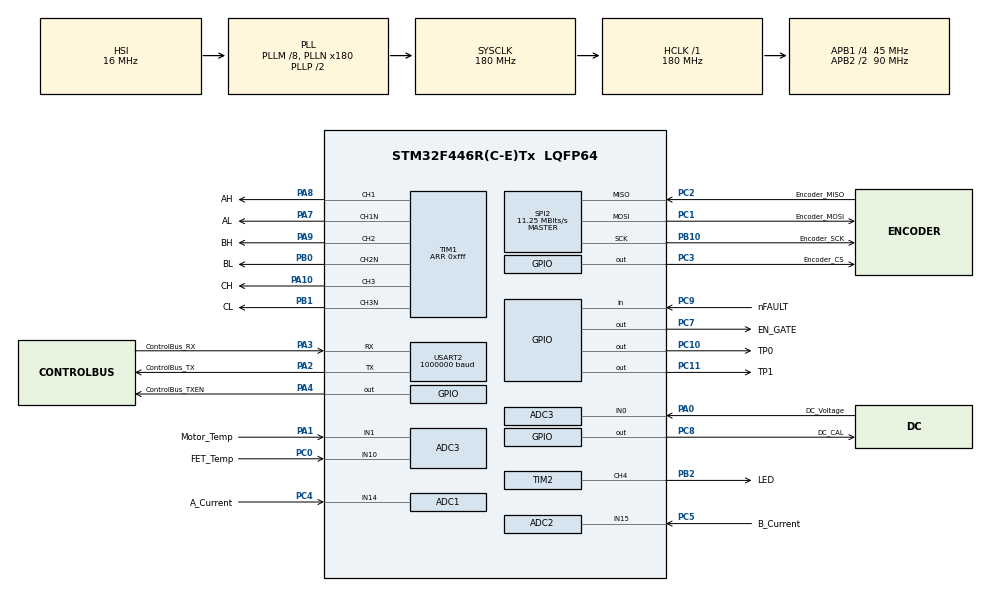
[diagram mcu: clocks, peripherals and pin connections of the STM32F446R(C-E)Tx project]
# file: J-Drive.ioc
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ADC1.Channel-0\#ChannelRegularConversion=ADC_CHANNEL_14
ADC1.ClockPrescaler=ADC_CLOCK_SYNC_PCLK_DIV4
ADC1.ExternalTrigConv=ADC_EXTERNALTRIGCONV_T8_TRGO
ADC1.NbrOfConversion=1
ADC1.NbrOfConversionFlag=1
ADC1.Rank-0\#ChannelRegularConversion=1
ADC1.SamplingTime-0\#ChannelRegularConversion=ADC_SAMPLETIME_3CYCLES
ADC1.master=1
ADC2.Channel-0\#ChannelRegularConversion=ADC_CHANNEL_15
ADC2.ClockPrescaler=ADC_CLOCK_SYNC_PCLK_DIV4
ADC2.ExternalTrigConv=ADC_EXTERNALTRIGCONV_T8_TRGO
ADC2.NbrOfConversion=1
ADC2.NbrOfConversionFlag=1
ADC2.Rank-0\#ChannelRegularConversion=1
ADC2.SamplingTime-0\#ChannelRegularConversion=ADC_SAMPLETIME_3CYCLES
ADC3.Channel-0\#ChannelRegularConversion=ADC_CHANNEL_0
ADC3.Channel-1\#ChannelRegularConversion=ADC_CHANNEL_1
ADC3.Channel-2\#ChannelRegularConversion=ADC_CHANNEL_10
ADC3.ClockPrescaler=ADC_CLOCK_SYNC_PCLK_DIV4
ADC3.DiscontinuousConvMode=ENABLE
ADC3.ExternalTrigConv=ADC_EXTERNALTRIGCONV_T8_TRGO
ADC3.InjNumberOfConversion=0
ADC3.NbrOfConversion=3
ADC3.NbrOfConversionFlag=1
ADC3.NbrOfDiscConversion=1
ADC3.Rank-0\#ChannelRegularConversion=1
ADC3.Rank-1\#ChannelRegularConversion=2
ADC3.Rank-2\#ChannelRegularConversion=3
ADC3.SamplingTime-0\#ChannelRegularConversion=ADC_SAMPLETIME_3CYCLES
ADC3.SamplingTime-1\#ChannelRegularConversion=ADC_SAMPLETIME_3CYCLES
ADC3.SamplingTime-2\#ChannelRegularConversion=ADC_SAMPLETIME_3CYCLES
ADC3.ScanConvMode=ENABLE
Dma.Request0=USART2_RX
Dma.USART2_RX.0.Direction=DMA_PERIPH_TO_MEMORY
Dma.USART2_RX.0.FIFOMode=DMA_FIFOMODE_DISABLE
Dma.USART2_RX.0.Instance=DMA1_Stream5
Dma.USART2_RX.0.MemDataAlignment=DMA_MDATAALIGN_BYTE
Dma.USART2_RX.0.MemInc=DMA_MINC_ENABLE
Dma.USART2_RX.0.Mode=DMA_CIRCULAR
Dma.USART2_RX.0.PeriphDataAlignment=DMA_PDATAALIGN_BYTE
Dma.USART2_RX.0.PeriphInc=DMA_PINC_DISABLE
Dma.USART2_RX.0.Priority=DMA_PRIORITY_LOW
Mcu.Family=STM32F4
Mcu.Name=STM32F446R(C-E)Tx
Mcu.Package=LQFP64
Mcu.UserConstants=DEADTIME_CLK,0
NVIC.DMA1_Stream5_IRQn=true\:0\:0\:false\:false\:true\:false\:true
NVIC.PriorityGroup=NVIC_PRIORITYGROUP_2
NVIC.SPI2_IRQn=true\:3\:3\:true\:false\:true\:true\:true
NVIC.TIM1_UP_TIM10_IRQn=true\:1\:1\:true\:false\:true\:true\:true
NVIC.TIM8_UP_TIM13_IRQn=true\:1\:1\:true\:false\:true\:true\:true
NVIC.USART2_IRQn=true\:1\:1\:true\:false\:true\:true\:true
PA0-WKUP.GPIO_Label=DC_Voltage
PA0-WKUP.Signal=ADCx_IN0
PA1.GPIO_Label=Motor_Temp
PA1.Signal=ADCx_IN1
PA10.GPIO_Label=CH
PA10.Signal=S_TIM1_CH3
PA13.GPIO_Label=TMS
PA13.Mode=Serial_Wire
PA13.Signal=SYS_JTMS-SWDIO
PA14.GPIO_Label=TCK
PA14.Mode=Serial_Wire
PA14.Signal=SYS_JTCK-SWCLK
PA2.GPIO_Label=ControlBus_TX
PA2.GPIO_PuPd=GPIO_PULLUP
PA2.Mode=Asynchronous
PA2.Signal=USART2_TX
PA3.GPIO_Label=ControlBus_RX
PA3.GPIO_PuPd=GPIO_PULLUP
PA3.Mode=Asynchronous
PA3.Signal=USART2_RX
PA4.GPIO_Label=ControlBus_TXEN
PA4.GPIO_Speed=GPIO_SPEED_FREQ_VERY_HIGH
PA4.Signal=GPIO_Output
PA7.GPIO_Label=AL
PA7.Mode=PWM Generation1 CH1 CH1N
PA7.Signal=TIM1_CH1N
PA8.GPIO_Label=AH
PA8.Signal=S_TIM1_CH1
PA9.GPIO_Label=BH
PA9.Signal=S_TIM1_CH2
PB0.GPIO_Label=BL
PB0.Mode=PWM Generation2 CH2 CH2N
PB0.Signal=TIM1_CH2N
PB1.GPIO_Label=CL
PB1.Mode=PWM Generation3 CH3 CH3N
PB1.Signal=TIM1_CH3N
PB10.GPIO_Label=Encoder_SCK
PB10.Mode=Full_Duplex_Master
PB10.Signal=SPI2_SCK
PB2.GPIO_Label=LED
PB2.Signal=S_TIM2_CH4
PB3.GPIO_Label=SWO
PB3.Signal=SYS_JTDO-SWO
PC0.GPIO_Label=FET_Temp
PC0.Signal=ADCx_IN10
PC1.GPIO_Label=Encoder_MOSI
PC1.Mode=Full_Duplex_Master
PC1.Signal=SPI2_MOSI
PC10.GPIO_Label=TP0
PC10.GPIO_ModeDefaultOutputPP=GPIO_MODE_OUTPUT_PP
PC10.GPIO_Speed=GPIO_SPEED_FREQ_VERY_HIGH
PC10.Signal=GPIO_Output
PC11.GPIO_Label=TP1
PC11.GPIO_Speed=GPIO_SPEED_FREQ_VERY_HIGH
PC11.Signal=GPIO_Output
PC2.GPIO_Label=Encoder_MISO
PC2.GPIO_PuPd=GPIO_NOPULL
PC2.Mode=Full_Duplex_Master
PC2.Signal=SPI2_MISO
PC3.GPIO_Label=Encoder_CS
PC3.Signal=GPIO_Output
PC4.GPIO_Label=A_Current
PC4.Signal=ADCx_IN14
PC5.GPIO_Label=B_Current
PC5.Signal=ADCx_IN15
PC7.GPIO_Label=EN_GATE
PC7.Signal=GPIO_Output
PC8.GPIO_Label=DC_CAL
PC8.Signal=GPIO_Output
PC9.GPIO_Label=nFAULT
PC9.GPIO_PuPd=GPIO_PULLUP
PC9.Signal=GPIO_Input
ProjectManager.HeapSize=0xFF00
ProjectManager.StackSize=0xFF00
ProjectManager.TargetToolchain=STM32CubeIDE
RCC.48MHZClocksFreq_Value=84000000
RCC.AHBFreq_Value=180000000
RCC.APB1CLKDivider=RCC_HCLK_DIV4
RCC.APB1Freq_Value=45000000
RCC.APB1TimFreq_Value=90000000
RCC.APB2CLKDivider=RCC_HCLK_DIV2
RCC.APB2Freq_Value=90000000
RCC.APB2TimFreq_Value=180000000
RCC.CortexFreq_Value=180000000
RCC.FLatency-AdvancedSettings=FLASH_LATENCY_5
RCC.HCLKFreq_Value=180000000
RCC.HSE_VALUE=8000000
RCC.HSI_VALUE=16000000
RCC.PLLM=8
RCC.PLLN=180
RCC.SYSCLKFreq_VALUE=180000000
RCC.SYSCLKSource=RCC_SYSCLKSOURCE_PLLCLK
RCC.USBFreq_Value=180000000
RCC.VCOOutputFreq_Value=360000000
SH.ADCx_IN0.0=ADC3_IN0,IN0
SH.ADCx_IN1.0=ADC3_IN1,IN1
SH.ADCx_IN10.0=ADC3_IN10,IN10
SH.ADCx_IN14.0=ADC1_IN14,IN14
SH.ADCx_IN15.0=ADC2_IN15,IN15
SH.S_TIM1_CH1.0=TIM1_CH1,PWM Generation1 CH1 CH1N
SH.S_TIM1_CH2.0=TIM1_CH2,PWM Generation2 CH2 CH2N
SH.S_TIM1_CH3.0=TIM1_CH3,PWM Generation3 CH3 CH3N
SH.S_TIM2_CH4.0=TIM2_CH4,PWM Generation4 CH4
SPI2.BaudRatePrescaler=SPI_BAUDRATEPRESCALER_4
SPI2.CLKPhase=SPI_PHASE_2EDGE
SPI2.CalculateBaudRate=11.25 MBits/s
SPI2.Direction=SPI_DIRECTION_2LINES
SPI2.Mode=SPI_MODE_MASTER
SPI2.VirtualType=VM_MASTER
TIM1.Channel-PWM\ Generation1\ CH1\ CH1N=TIM_CHANNEL_1
TIM1.Channel-PWM\ Generation2\ CH2\ CH2N=TIM_CHANNEL_2
TIM1.Channel-PWM\ Generation3\ CH3\ CH3N=TIM_CHANNEL_3
TIM1.ClockDivision=TIM_CLOCKDIVISION_DIV1
TIM1.CounterMode=TIM_COUNTERMODE_CENTERALIGNED2
TIM1.DeadTime=DEADTIME_CLK
TIM1.Period=0xfff
TIM1.RepetitionCounter=1
TIM2.Channel-PWM\ Generation4\ CH4=TIM_CHANNEL_4
TIM2.Period=0xfff
TIM8.Period=0xfff
TIM8.TIM_MasterOutputTrigger=TIM_TRGO_UPDATE
TIM8.TIM_MasterSlaveMode=TIM_MASTERSLAVEMODE_ENABLE
USART2.BaudRate=1000000
USART2.OverSampling=UART_OVERSAMPLING_16
USART2.VirtualMode=VM_ASYNC
VP_CRC_VS_CRC.Mode=CRC_Activate
VP_TIM1_VS_ClockSourceINT.Mode=Internal
VP_TIM2_VS_ClockSourceINT.Mode=Internal
VP_TIM8_VS_ClockSourceINT.Mode=Internal
board=NUCLEO-F446RE

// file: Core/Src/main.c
/* USER CODE BEGIN Header */
/**
  ******************************************************************************
  * @file           : main.c
  * @brief          : Main program body
  ******************************************************************************
  * @attention
  *
  * <h2><center>&copy; Copyright (c) 2020 STMicroelectronics.
  * All rights reserved.</center></h2>
  *
  * This software component is licensed by ST under BSD 3-Clause license,
  * the "License"; You may not use this file except in compliance with the
  * License. You may obtain a copy of the License at:
  *                        opensource.org/licenses/BSD-3-Clause
  *
  ******************************************************************************
  */
/* USER CODE END Header */
#include "main.h"
#include "adc.h"
#include "crc.h"
#include "dma.h"
#include "spi.h"
#include "tim.h"
#include "usart.h"
#include "gpio.h"

/* USER CODE BEGIN Includes */
#include <jdrive_main.hpp>
/* USER CODE END Includes */

void SystemClock_Config(void);
/* USER CODE BEGIN PFP */
int _write(int fd, char *str, int len)
{
	HAL_GPIO_WritePin(ControlBus_TXEN_GPIO_Port, ControlBus_TXEN_Pin, GPIO_PIN_SET);
	HAL_UART_Transmit_IT(&huart2, (uint8_t *)str, len);
	return len;
}

/* USER CODE END PFP */

int main(void)
{

  /* MCU Configuration--------------------------------------------------------*/

  /* Reset of all peripherals, Initializes the Flash interface and the Systick. */
  HAL_Init();

  /* Configure the system clock */
  SystemClock_Config();

  /* Initialize all configured peripherals */
  MX_GPIO_Init();
  MX_DMA_Init();
  MX_TIM2_Init();
  MX_CRC_Init();
  MX_USART2_UART_Init();
  MX_ADC1_Init();
  MX_ADC2_Init();
  MX_ADC3_Init();
  MX_SPI2_Init();
  MX_TIM1_Init();
  MX_TIM8_Init();
  /* USER CODE BEGIN 2 */
  HAL_GPIO_WritePin(DC_CAL_GPIO_Port, DC_CAL_Pin, GPIO_PIN_RESET);
  HAL_GPIO_WritePin(EN_GATE_GPIO_Port, EN_GATE_Pin, GPIO_PIN_RESET);

  JDriveMain();
  /* USER CODE END 2 */

  /* Infinite loop */
  while (1)
  {

  }
}

void SystemClock_Config(void)
{
  RCC_OscInitTypeDef RCC_OscInitStruct = {0};
  RCC_ClkInitTypeDef RCC_ClkInitStruct = {0};

  /** Configure the main internal regulator output voltage
  */
  __HAL_RCC_PWR_CLK_ENABLE();
  __HAL_PWR_VOLTAGESCALING_CONFIG(PWR_REGULATOR_VOLTAGE_SCALE1);
  /** Initializes the RCC Oscillators according to the specified parameters
  * in the RCC_OscInitTypeDef structure.
  */
  RCC_OscInitStruct.OscillatorType = RCC_OSCILLATORTYPE_HSI;
  RCC_OscInitStruct.HSIState = RCC_HSI_ON;
  RCC_OscInitStruct.HSICalibrationValue = RCC_HSICALIBRATION_DEFAULT;
  RCC_OscInitStruct.PLL.PLLState = RCC_PLL_ON;
  RCC_OscInitStruct.PLL.PLLSource = RCC_PLLSOURCE_HSI;
  RCC_OscInitStruct.PLL.PLLM = 8;
  RCC_OscInitStruct.PLL.PLLN = 180;
  RCC_OscInitStruct.PLL.PLLP = RCC_PLLP_DIV2;
  RCC_OscInitStruct.PLL.PLLQ = 2;
  RCC_OscInitStruct.PLL.PLLR = 2;
  if (HAL_RCC_OscConfig(&RCC_OscInitStruct) != HAL_OK)
  {
    Error_Handler();
  }
  /** Activate the Over-Drive mode
  */
  if (HAL_PWREx_EnableOverDrive() != HAL_OK)
  {
    Error_Handler();
  }
  /** Initializes the CPU, AHB and APB buses clocks
  */
  RCC_ClkInitStruct.ClockType = RCC_CLOCKTYPE_HCLK|RCC_CLOCKTYPE_SYSCLK
                              |RCC_CLOCKTYPE_PCLK1|RCC_CLOCKTYPE_PCLK2;
  RCC_ClkInitStruct.SYSCLKSource = RCC_SYSCLKSOURCE_PLLCLK;
  RCC_ClkInitStruct.AHBCLKDivider = RCC_SYSCLK_DIV1;
  RCC_ClkInitStruct.APB1CLKDivider = RCC_HCLK_DIV4;
  RCC_ClkInitStruct.APB2CLKDivider = RCC_HCLK_DIV2;

  if (HAL_RCC_ClockConfig(&RCC_ClkInitStruct, FLASH_LATENCY_5) != HAL_OK)
  {
    Error_Handler();
  }
}

void Error_Handler(void)
{
}

/************************ (C) COPYRIGHT STMicroelectronics *****END OF FILE****/
